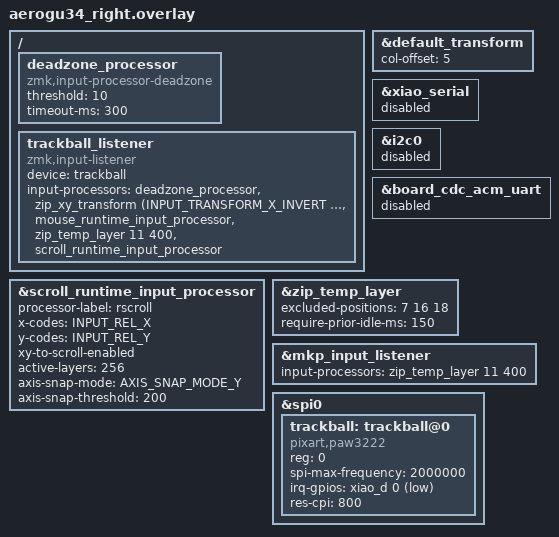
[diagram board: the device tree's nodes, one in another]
#include "aerogu34.dtsi"
#include <behaviors.dtsi>
#include <input/processors.dtsi>
#include <input/processors/runtime-input-processor.dtsi>
#include <dt-bindings/zmk/runtime_input_processor.h>
#include <dt-bindings/zmk/input_transform.h>

&default_transform {
    col-offset = <5>;
};

&xiao_serial { status = "disabled"; };

/* Disable I2C0 to prevent conflict with SPI0 (same hardware peripheral). */
&i2c0 { status = "disabled"; };

/* Disable the board's default UART-over-USB-CDC-ACM endpoint.
 * Zephyr 4's xiao_ble board unconditionally adds a second CDC ACM USB
 * function for console/shell. With the studio-rpc-usb-uart snippet that
 * adds another CDC ACM for the Studio RPC channel, the device ends up
 * exposing two CDC ACMs and DYA Studio's Web Serial port-open fails
 * ("The port is already open" / wrong port chosen). We don't use the
 * console, so drop the node. */
&board_cdc_acm_uart { status = "disabled"; };

&scroll_runtime_input_processor {
    processor-label = "rscroll";
    x-codes = <INPUT_REL_X>;
    y-codes = <INPUT_REL_Y>;
    xy-to-scroll-enabled;
    /* Hiro keymap: BIT(8) = layer 8 (SymNum)。SymNumホールド中はトラボがスクロール
     * (LiNEA40のscroll-layers=<8>と同じ操作感)。upstreamの既定はBIT(3)=<8>。 */
    active-layers = <256>;
    axis-snap-mode = <AXIS_SNAP_MODE_Y>;
    axis-snap-threshold = <200>;
};

/* v1.6: AML（temp layer）の調整
 * - excluded-positions: クリック3キー（7=I/MB3, 16=J/MB1, 18=L/MB2）の押下では
 *   レイヤーを解除しない
 * - require-prior-idle-ms: 直前150ms以内にキー入力があれば玉が動いても
 *   AMLを発動しない（タイピング中の玉ブレ対策） */
&zip_temp_layer {
    excluded-positions = <7 16 18>;
    require-prior-idle-ms = <150>;
};

/* v1.6の要: クリック（&mkp）のイベント自体をzip_temp_layerに流す。
 * これによりクリックのたびに解除タイマーが400msで再装填され、
 * 玉が静止したままでも連打が続く限りAMLが維持される
 * （日本のZMKトラボ界隈で使われている公知のテクニック。roBa等で実績あり） */
&mkp_input_listener {
    input-processors = <&zip_temp_layer 11 400>;
};

/ {
    deadzone_processor: deadzone_processor {
        compatible = "zmk,input-processor-deadzone";
        #input-processor-cells = <0>;
        threshold = <10>;
        timeout-ms = <300>;
    };

    trackball_listener: trackball_listener {
        compatible = "zmk,input-listener";
        device = <&trackball>;
        /* Chain order:
         *   deadzone  - filter sub-threshold noise
         *   xy_transform - invert both axes (sensor-mounting orientation)
         *   mouse_runtime - DYA Studio runtime config (CPI / snipe / etc)
         *   temp_layer 11 400ms - auto-enable Mouse layer on movement,
         *     turn back off 0.4s after the last trackball motion OR click
         *     (v1.6: クリック延命は&mkp_input_listener側の同プロセッサ適用で実現。
         *      upstream既定は 4 1000)
         *   scroll_runtime - convert XY -> scroll on SymNum layer only */
        input-processors = <&deadzone_processor
                            &zip_xy_transform (INPUT_TRANSFORM_X_INVERT | INPUT_TRANSFORM_Y_INVERT)
                            &mouse_runtime_input_processor
                            &zip_temp_layer 11 400
                            &scroll_runtime_input_processor>;
    };
};

&spi0 {
    status = "okay";

    trackball: trackball@0 {
        status = "okay";
        compatible = "pixart,paw3222";
        reg = <0>;
        spi-max-frequency = <2000000>;
        irq-gpios = <&xiao_d 0 (GPIO_ACTIVE_LOW | GPIO_PULL_UP)>;
        /* Boot-time sensor CPI (counts per inch). Valid range 608-4826 in
         * steps of 38; driver rounds down. 800 maps to 21*38 = 798.
         * DYA Studio's runtime-input-processor can override at runtime. */
        res-cpi = <800>;
    };
};
